# spimss_reva_me10 register map
Registers are access not given, no defined reset value unless marked. A register's access mark holds for its fields unless they carry their own. Offsets are from the block's base; lines under a group give offsets from that group; [hi:lo] are bit positions; {n}, {i} and the like mark numbered series; 'fields as' and 'values as' point back to an identical list; <NAME> marks a mode.

## Memory map
0x40018000 SPIMSS size 0x1000 — Serial Peripheral Interface.

## SPIMSS — Serial Peripheral Interface.
Base 0x40018000; register names take the prefix SPIMSS
0x00 DATA rw — SPI 16-bit Data Access
  [15:0] DATA — SPI data.
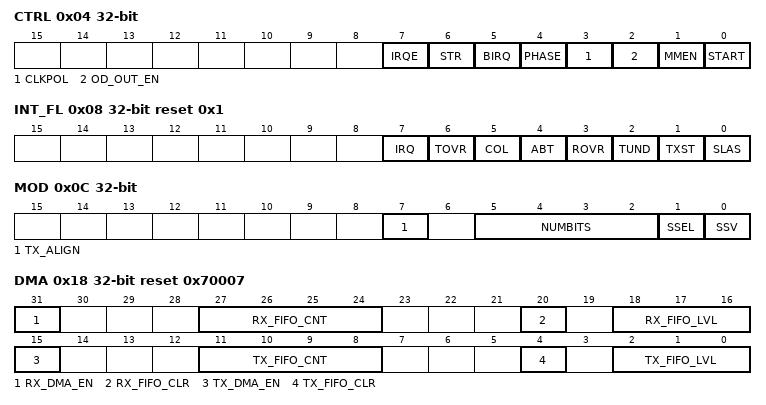
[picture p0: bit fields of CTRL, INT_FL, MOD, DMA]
0x04 CTRL — SPI Control Register.
  [7] IRQE — Interrupt Request Enable.
    0=dis; 1=en
  [6] STR — Start SPI Interrupt.
    0=complete (No operation/complete.); 1=Start operation
  [5] BIRQ — Baud Rate Generator Timer Interrupt Request.
    0=dis; 1=en
  [4] PHASE — Phase Select.
    0=activeEdge (Transmit on active edge of SCLK.); 1=inactiveEdge (Transmit on inactive edge of SCLK.)
  [3] CLKPOL — Clock Polarity.
    0=idleLo (SCLK idles Low (0) after character transmission/reception.); 1=idleHi (SCLK idles High (1) after character transmission/reception.)
  [2] OD_OUT_EN — Wired OR (open drain) Enable.
    0=dis; 1=en
  [1] MMEN — SPI Master Mode Enable.
    0=slave; 1=master
  [0] START — SPI Enable.
    0=stop; 1=start
0x08 INT_FL reset 0x1 — SPI Interrupt Flag Register.
  [7] IRQ write-1-clears — SPI Interrupt Request.
    0=inactive (No interrupt is pending.); 1=pending (An interrupt is pending.)
  [6] TOVR — Transmit Overrun.
    0=noEvent (The event has not occurred.); 1=overrun (The event has occurred.)
  [5] COL — Collision.
    0=noEvent (The event has not occurred.); 1=collision (The event has occurred.)
  [4] ABT — Slave Mode Transaction Abort.
    0=noEvent (The event has not occurred.); 1=aborted (The event has occurred.)
  [3] ROVR — Receive Overrun.
    values as TOVR
  [2] TUND write-1-clears — Transmit Underrun.
    0=noEvent (The event has not occurred.); 1=underrun (The event has occurred.)
  [1] TXST ro — Transmit Status.
    0=idle; 1=busy
  [0] SLAS ro — Slave Select. If the SPI is in slave mode, this bit indicates if the SPI is selected. If the SPI is in master mode this bit has no meaning.
    0=selected; 1=notSelected
0x0C MOD — SPI Mode Register.
  [7] TX_ALIGN — Transmit Left Justify.
    0=lsb; 1=msb
  [5:2] NUMBITS
    0=16bits; {v}={v}bits (v=1..15)
  [1] SSEL — Slave Select I/O.
    0=input; 1=output
  [0] SSV — Slave Select Value.
    0=lo (The SSEL pin will be driven low.); 1=hi (The SSEL pin will be driven high.)
0x14 BRG reset 0xFFFF — Baud Rate Reload Value. The SPI Baud Rate register is a 16-bit reload value for the SPI Baud Rate Generator. The reload value must be greater than or equal to 0002H for proper SPI operation (maximum baud rate is PCLK frequency divided by 4).
  [15:0] DIV — Baud Rate Reload Value.
0x18 DMA reset 0x70007 — SPI DMA Register.
  [31] RX_DMA_EN — Receive DMA Enable.
    0=dis; 1=en
  [27:24] RX_FIFO_CNT ro — Receive FIFO Count.
  [20] RX_FIFO_CLR — Receive FIFO Clear.
    1=clear (Start RX FIFO clear operation.)
  [18:16] RX_FIFO_LVL — Receive FIFO Level. Sets the RX FIFO DMA request threshold. This configures the number of filled RxFIFO entries before activating an RxDMA request.
    {v}={v+1}entries (v=0..7)
  [15] TX_DMA_EN — Transmit DMA Enable.
    0=dis; 1=en
  [11:8] TX_FIFO_CNT ro — Transmit FIFO Count.
  [4] TX_FIFO_CLR wo — Transmit FIFO Clear.
    1=clear (Start TX FIFO Clear operation.)
  [2:0] TX_FIFO_LVL — Transmit FIFO Level. Set the number of free entries in the TxFIFO when a TxDMA request occurs.
    {v}={v+1}entries (v=0..7)
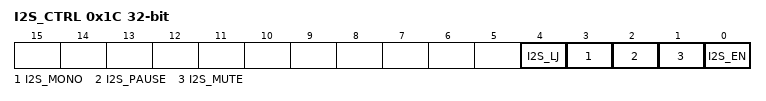
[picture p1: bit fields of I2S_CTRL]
0x1C I2S_CTRL — I2S Control Register.
  [4] I2S_LJ — I2S Left Justify.
    0=lag (Normal I2S audio protocol.); 1=syncronized (Audio data is synchronized with SSEL.)
  [3] I2S_MONO — I2S Monophonic Audio Mode.
    0=Stereophonic audio; 1=Monophonic audio format.Each transmit data word is replicated on both left/right channels. Receive data is taken from left channel, right channel receive data is ignored.
  [2] I2S_PAUSE — I2S Pause transmit/receive.
    0=Normal Transmit; 1=pause (Halt transmit and receive FIFO and DMA access, transmit 0's.)
  [1] I2S_MUTE — I2S Mute transmit.
    0=Normal Transmit; 1=muted (Transmit data is replaced with 0.)
  [0] I2S_EN — I2S Mode Enable.
    0=dis; 1=en
